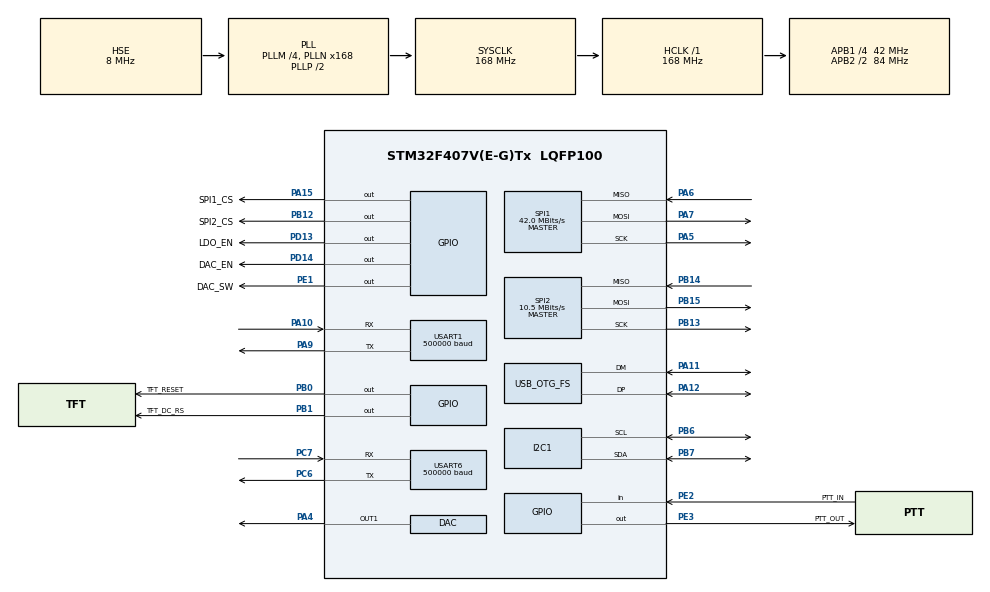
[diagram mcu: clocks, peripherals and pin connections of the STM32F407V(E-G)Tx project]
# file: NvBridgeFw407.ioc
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Mcu.Family=STM32F4
Mcu.Name=STM32F407V(E-G)Tx
Mcu.Package=LQFP100
NVIC.OTG_FS_IRQn=true\:0\:0\:false\:false\:true\:false\:true\:true
NVIC.PriorityGroup=NVIC_PRIORITYGROUP_4
NVIC.SPI2_IRQn=true\:0\:0\:false\:false\:true\:true\:true\:true
PA10.Mode=Asynchronous
PA10.Signal=USART1_RX
PA11.Mode=Device_Only
PA11.Signal=USB_OTG_FS_DM
PA12.Mode=Device_Only
PA12.Signal=USB_OTG_FS_DP
PA13.Mode=Serial_Wire
PA13.Signal=SYS_JTMS-SWDIO
PA14.Mode=Serial_Wire
PA14.Signal=SYS_JTCK-SWCLK
PA15.GPIO_Label=SPI1_CS
PA15.GPIO_PuPd=GPIO_PULLUP
PA15.GPIO_Speed=GPIO_SPEED_FREQ_LOW
PA15.Signal=GPIO_Output
PA4.Signal=COMP_DAC1_group
PA5.Mode=Full_Duplex_Master
PA5.Signal=SPI1_SCK
PA6.Mode=Full_Duplex_Master
PA6.Signal=SPI1_MISO
PA7.Mode=Full_Duplex_Master
PA7.Signal=SPI1_MOSI
PA9.Mode=Asynchronous
PA9.Signal=USART1_TX
PB0.GPIO_Label=TFT_RESET
PB0.Signal=GPIO_Output
PB1.GPIO_Label=TFT_DC_RS
PB1.Signal=GPIO_Output
PB12.GPIO_Label=SPI2_CS
PB12.GPIO_PuPd=GPIO_PULLUP
PB12.Signal=GPIO_Output
PB13.Mode=Full_Duplex_Master
PB13.Signal=SPI2_SCK
PB14.Mode=Full_Duplex_Master
PB14.Signal=SPI2_MISO
PB15.Mode=Full_Duplex_Master
PB15.Signal=SPI2_MOSI
PB6.GPIO_Pu=GPIO_PULLUP
PB6.Mode=I2C
PB6.Signal=I2C1_SCL
PB7.GPIO_Pu=GPIO_PULLUP
PB7.Mode=I2C
PB7.Signal=I2C1_SDA
PC6.Mode=Asynchronous
PC6.Signal=USART6_TX
PC7.Mode=Asynchronous
PC7.Signal=USART6_RX
PD13.GPIO_Label=LDO_EN
PD13.Signal=GPIO_Output
PD14.GPIO_Label=DAC_EN
PD14.Signal=GPIO_Output
PE1.GPIO_Label=DAC_SW
PE1.Signal=GPIO_Output
PE2.GPIO_Label=PTT_IN
PE2.GPIO_PuPd=GPIO_PULLUP
PE2.Signal=GPIO_Input
PE3.GPIO_Label=PTT_OUT
PE3.GPIO_PuPd=GPIO_PULLUP
PE3.PinState=GPIO_PIN_SET
PE3.Signal=GPIO_Output
PH0-OSC_IN.Mode=HSE-External-Oscillator
PH0-OSC_IN.Signal=RCC_OSC_IN
PH1-OSC_OUT.Mode=HSE-External-Oscillator
PH1-OSC_OUT.Signal=RCC_OSC_OUT
ProjectManager.HeapSize=0x200
ProjectManager.StackSize=0x400
ProjectManager.TargetToolchain=STM32CubeIDE
RCC.48MHZClocksFreq_Value=48000000
RCC.AHBFreq_Value=168000000
RCC.APB1CLKDivider=RCC_HCLK_DIV4
RCC.APB1Freq_Value=42000000
RCC.APB1TimFreq_Value=84000000
RCC.APB2CLKDivider=RCC_HCLK_DIV2
RCC.APB2Freq_Value=84000000
RCC.APB2TimFreq_Value=168000000
RCC.CortexFreq_Value=168000000
RCC.HCLKFreq_Value=168000000
RCC.HSE_VALUE=8000000
RCC.HSI_VALUE=16000000
RCC.LSE_VALUE=32768
RCC.PLLM=4
RCC.PLLN=168
RCC.PLLQ=7
RCC.SYSCLKFreq_VALUE=168000000
RCC.SYSCLKSource=RCC_SYSCLKSOURCE_PLLCLK
RCC.VCOOutputFreq_Value=336000000
SH.COMP_DAC1_group.0=DAC_OUT1,DAC_OUT1
SPI1.BaudRatePrescaler=SPI_BAUDRATEPRESCALER_2
SPI1.CalculateBaudRate=42.0 MBits/s
SPI1.Direction=SPI_DIRECTION_2LINES
SPI1.Mode=SPI_MODE_MASTER
SPI1.VirtualType=VM_MASTER
SPI2.BaudRatePrescaler=SPI_BAUDRATEPRESCALER_4
SPI2.CLKPhase=SPI_PHASE_1EDGE
SPI2.CLKPolarity=SPI_POLARITY_LOW
SPI2.CalculateBaudRate=10.5 MBits/s
SPI2.DataSize=SPI_DATASIZE_8BIT
SPI2.Direction=SPI_DIRECTION_2LINES
SPI2.Mode=SPI_MODE_MASTER
SPI2.VirtualType=VM_MASTER
USART1.BaudRate=500000
USART1.VirtualMode=VM_ASYNC
USART6.BaudRate=500000
USART6.VirtualMode=VM_ASYNC
USB_DEVICE.CLASS_NAME_FS=CDC
USB_DEVICE.MANUFACTURER_STRING-CDC_FS=Polyn Technology
USB_DEVICE.PRODUCT_STRING_CDC_FS=NvBox
USB_DEVICE.VirtualMode-CDC_FS=Cdc
USB_DEVICE.VirtualModeFS=Cdc_FS
USB_OTG_FS.VirtualMode=Device_Only
VP_USB_DEVICE_VS_USB_DEVICE_CDC_FS.Mode=CDC_FS
board=custom

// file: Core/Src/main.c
/* USER CODE BEGIN Header */
/**
  ******************************************************************************
  * @file           : main.c
  * @brief          : Main program body
  ******************************************************************************
  * @attention
  *
  * Copyright (c) 2025 STMicroelectronics.
  * All rights reserved.
  *
  * This software is licensed under terms that can be found in the LICENSE file
  * in the root directory of this software component.
  * If no LICENSE file comes with this software, it is provided AS-IS.
  *
  ******************************************************************************
  */
/* USER CODE END Header */
#include "main.h"
#include "dac.h"
#include "i2c.h"
#include "spi.h"
#include "usart.h"
#include "usb_device.h"
#include "gpio.h"

void SystemClock_Config(void);

/* USER CODE BEGIN 0 */
#ifndef CUBE_MAIN
void main_init(){
#else
/* USER CODE END 0 */

int main(void)
{

  /* USER CODE BEGIN 1 */
#endif
  /* USER CODE END 1 */

  /* MCU Configuration--------------------------------------------------------*/

  /* Reset of all peripherals, Initializes the Flash interface and the Systick. */
  HAL_Init();

  /* Configure the system clock */
  SystemClock_Config();

  /* Initialize all configured peripherals */
  MX_GPIO_Init();
  MX_USART1_UART_Init();
  MX_USB_DEVICE_Init();
  MX_DAC_Init();
  MX_I2C1_Init();
  MX_SPI2_Init();
  MX_USART6_UART_Init();
  MX_SPI1_Init();

  /* Infinite loop */
  /* USER CODE BEGIN WHILE */
#ifndef CUBE_MAIN
#else
  while (1)
  {
    /* USER CODE END WHILE */

    /* USER CODE BEGIN 3 */
  }
#endif
  /* USER CODE END 3 */
}

void SystemClock_Config(void)
{
  RCC_OscInitTypeDef RCC_OscInitStruct = {0};
  RCC_ClkInitTypeDef RCC_ClkInitStruct = {0};

  /** Configure the main internal regulator output voltage
  */
  __HAL_RCC_PWR_CLK_ENABLE();
  __HAL_PWR_VOLTAGESCALING_CONFIG(PWR_REGULATOR_VOLTAGE_SCALE1);

  /** Initializes the RCC Oscillators according to the specified parameters
  * in the RCC_OscInitTypeDef structure.
  */
  RCC_OscInitStruct.OscillatorType = RCC_OSCILLATORTYPE_HSE;
  RCC_OscInitStruct.HSEState = RCC_HSE_ON;
  RCC_OscInitStruct.PLL.PLLState = RCC_PLL_ON;
  RCC_OscInitStruct.PLL.PLLSource = RCC_PLLSOURCE_HSE;
  RCC_OscInitStruct.PLL.PLLM = 4;
  RCC_OscInitStruct.PLL.PLLN = 168;
  RCC_OscInitStruct.PLL.PLLP = RCC_PLLP_DIV2;
  RCC_OscInitStruct.PLL.PLLQ = 7;
  if (HAL_RCC_OscConfig(&RCC_OscInitStruct) != HAL_OK)
  {
    Error_Handler();
  }

  /** Initializes the CPU, AHB and APB buses clocks
  */
  RCC_ClkInitStruct.ClockType = RCC_CLOCKTYPE_HCLK|RCC_CLOCKTYPE_SYSCLK
                              |RCC_CLOCKTYPE_PCLK1|RCC_CLOCKTYPE_PCLK2;
  RCC_ClkInitStruct.SYSCLKSource = RCC_SYSCLKSOURCE_PLLCLK;
  RCC_ClkInitStruct.AHBCLKDivider = RCC_SYSCLK_DIV1;
  RCC_ClkInitStruct.APB1CLKDivider = RCC_HCLK_DIV4;
  RCC_ClkInitStruct.APB2CLKDivider = RCC_HCLK_DIV2;

  if (HAL_RCC_ClockConfig(&RCC_ClkInitStruct, FLASH_LATENCY_5) != HAL_OK)
  {
    Error_Handler();
  }
}

void Error_Handler(void)
{
  __disable_irq();
  while (1)
  {
  }
}
